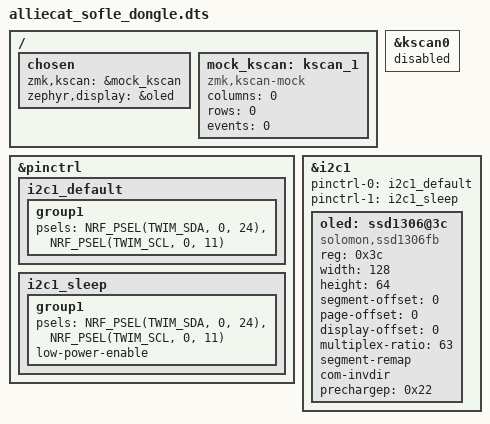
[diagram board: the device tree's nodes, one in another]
/*
*
* Copyright (c) 2021 Darryl deHaan
* SPDX-License-Identifier: MIT
*
*/

#include "alliecat_sofle.dtsi"

&kscan0 {
    status = "disabled";
};

&pinctrl {
    i2c1_default: i2c1_default {
        group1 {
            psels = <NRF_PSEL(TWIM_SDA, 0, 24)>,
                    <NRF_PSEL(TWIM_SCL, 0, 11)>;
        };
    };

    i2c1_sleep: i2c1_sleep {
        group1 {
            psels = <NRF_PSEL(TWIM_SDA, 0, 24)>,
                    <NRF_PSEL(TWIM_SCL, 0, 11)>;
            low-power-enable;
        };
    };
};

pro_micro_i2c: &i2c1 {
    status = "okay";
    pinctrl-0 = <&i2c1_default>;
    pinctrl-1 = <&i2c1_sleep>;
    pinctrl-names = "default", "sleep";

    oled: ssd1306@3c {
        compatible = "solomon,ssd1306fb";
        reg = <0x3c>;
        width = <128>;
        height = <64>;
        segment-offset = <0>;
        page-offset = <0>;
        display-offset = <0>;
        multiplex-ratio = <63>;
        segment-remap;
        com-invdir;
        prechargep = <0x22>;
    };
};

/{
    chosen {
        zmk,kscan = &mock_kscan;
        zephyr,display = &oled;
    };
    mock_kscan: kscan_1 {
        compatible = "zmk,kscan-mock";
        columns = <0>;
        rows = <0>;
        events = <0>;
    };
};

